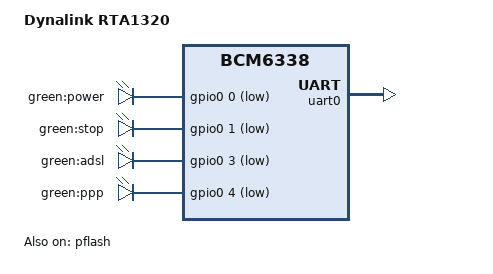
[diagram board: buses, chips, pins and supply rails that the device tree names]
#include "bcm6338.dtsi"

#include <dt-bindings/input/input.h>

/ {
	model = "Dynalink RTA1320";
	compatible = "dynalink,rta1320", "brcm,bcm6338";

	chosen {
		bootargs = "rootfstype=squashfs,jffs2 noinitrd console=ttyS0,115200";
		stdout-path = "serial0:115200n8";
	};

	leds {
		compatible = "gpio-leds";

		green_power {
			label = "green:power";
			gpios = <&gpio0 0 1>;
			default-state = "on";
		};
		green_stop {
			label = "green:stop";
			gpios = <&gpio0 1 1>;
		};
		green_adsl {
			label = "green:adsl";
			gpios = <&gpio0 3 1>;
		};
		green_ppp {
			label = "green:ppp";
			gpios = <&gpio0 4 1>;
		};
	};
};

&pflash {
	status = "okay";

	partitions {
		compatible = "fixed-partitions";
		#address-cells = <1>;
		#size-cells = <1>;

		cfe@0 {
			label = "CFE";
			reg = <0x000000 0x010000>;
			read-only;
		};

		linux@10000 {
			label = "linux";
			reg = <0x010000 0x3e0000>;
			compatible = "brcm,bcm963xx-imagetag";
		};

		nvram@3f0000 {
			label = "nvram";
			reg = <0x3f0000 0x010000>;
		};
	};
};

&uart0 {
	status = "okay";
};
